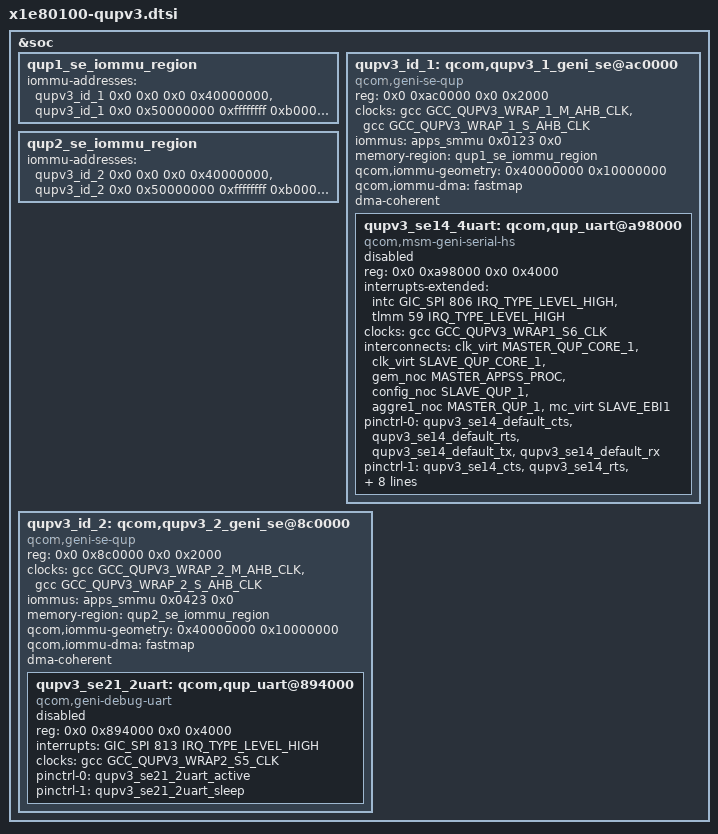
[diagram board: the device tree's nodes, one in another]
// SPDX-License-Identifier: BSD-3-Clause
/*
 * Copyright (c) Qualcomm Technologies, Inc. and/or its subsidiaries.
 */
#include <dt-bindings/clock/qcom,x1e80100-gcc.h>

&soc {
	qup1_se_iommu_region: qup1_se_iommu_region {
		iommu-addresses = <&qupv3_id_1 0x0 0x0 0x0 0x40000000>,
				  <&qupv3_id_1 0x0 0x50000000 0xffffffff 0xb0000000>;
	};

	qupv3_id_1: qcom,qupv3_1_geni_se@ac0000 {
		compatible = "qcom,geni-se-qup";
		reg = <0x0 0xac0000 0x0 0x2000>;
		clock-names = "m-ahb", "s-ahb";
		clocks = <&gcc GCC_QUPV3_WRAP_1_M_AHB_CLK>,
			 <&gcc GCC_QUPV3_WRAP_1_S_AHB_CLK>;
		iommus = <&apps_smmu 0x0123 0x0>;
		memory-region = <&qup1_se_iommu_region>;
		qcom,iommu-geometry = <0x40000000 0x10000000>;
		qcom,iommu-dma = "fastmap";
		dma-coherent;
		#address-cells = <2>;
		#size-cells = <2>;
		ranges;
		status = "okay";

		qupv3_se14_4uart: qcom,qup_uart@a98000 {
			compatible = "qcom,msm-geni-serial-hs";
			reg = <0x0 0xa98000 0x0 0x4000>;
			reg-names = "se_phys";
			interrupts-extended = <&intc GIC_SPI 806 IRQ_TYPE_LEVEL_HIGH>,
					      <&tlmm 59 IRQ_TYPE_LEVEL_HIGH>;
			clock-names = "se-clk";
			clocks = <&gcc GCC_QUPV3_WRAP1_S6_CLK>;
			interconnect-names = "qup-core", "qup-config", "qup-memory";
			interconnects = <&clk_virt MASTER_QUP_CORE_1 &clk_virt SLAVE_QUP_CORE_1>,
					<&gem_noc MASTER_APPSS_PROC &config_noc SLAVE_QUP_1>,
					<&aggre1_noc MASTER_QUP_1 &mc_virt SLAVE_EBI1>;
			pinctrl-names = "default", "active", "sleep", "shutdown";
			pinctrl-0 = <&qupv3_se14_default_cts>, <&qupv3_se14_default_rts>,
				    <&qupv3_se14_default_tx>, <&qupv3_se14_default_rx>;
			pinctrl-1 = <&qupv3_se14_cts>, <&qupv3_se14_rts>,
				    <&qupv3_se14_tx>, <&qupv3_se14_rx_active>;
			pinctrl-2 = <&qupv3_se14_cts>, <&qupv3_se14_rts>,
				    <&qupv3_se14_tx>, <&qupv3_se14_rx_wake>;
			pinctrl-3 = <&qupv3_se14_default_cts>, <&qupv3_se14_default_rts>,
				    <&qupv3_se14_default_tx>, <&qupv3_se14_default_rx>;
			qcom,wakeup-byte = <0xFD>;
			qcom,suspend-ignore-children;
			status = "disabled";
		};
	};

	qup2_se_iommu_region: qup2_se_iommu_region {
		iommu-addresses = <&qupv3_id_2 0x0 0x0 0x0 0x40000000>,
				  <&qupv3_id_2 0x0 0x50000000 0xffffffff 0xb0000000>;
	};

	qupv3_id_2: qcom,qupv3_2_geni_se@8c0000 {
		compatible = "qcom,geni-se-qup";
		reg = <0x0 0x8c0000 0x0 0x2000>;
		clock-names = "m-ahb", "s-ahb";
		clocks = <&gcc GCC_QUPV3_WRAP_2_M_AHB_CLK>,
			 <&gcc GCC_QUPV3_WRAP_2_S_AHB_CLK>;
		iommus = <&apps_smmu 0x0423 0x0>;
		memory-region = <&qup2_se_iommu_region>;
		qcom,iommu-geometry = <0x40000000 0x10000000>;
		qcom,iommu-dma = "fastmap";
		dma-coherent;
		#address-cells = <2>;
		#size-cells = <2>;
		ranges;
		status = "okay";

		qupv3_se21_2uart: qcom,qup_uart@894000 {
			compatible = "qcom,geni-debug-uart";
			reg = <0x0 0x894000 0x0 0x4000>;
			reg-names = "se_phys";
			interrupts = <GIC_SPI 813 IRQ_TYPE_LEVEL_HIGH>;
			clock-names = "se";
			clocks = <&gcc GCC_QUPV3_WRAP2_S5_CLK>;
			pinctrl-names = "default", "sleep";
			pinctrl-0 = <&qupv3_se21_2uart_active>;
			pinctrl-1 = <&qupv3_se21_2uart_sleep>;
			status = "disabled";
		};
	};
};
